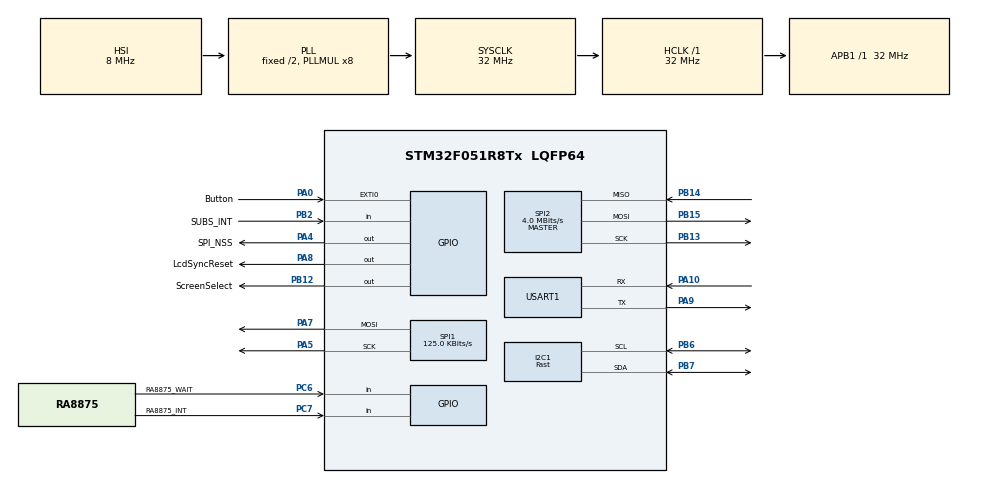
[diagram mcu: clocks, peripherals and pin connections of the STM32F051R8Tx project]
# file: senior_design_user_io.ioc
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I2C1.I2C_Speed_Mode=I2C_Fast
I2C1.Timing=0x0000020B
Mcu.Family=STM32F0
Mcu.Name=STM32F051R8Tx
Mcu.Package=LQFP64
NVIC.EXTI0_1_IRQn=true\:0\:0\:false\:false\:true\:true\:true
PA0.GPIO_Label=Button
PA0.GPIO_PuPd=GPIO_PULLDOWN
PA0.Signal=GPXTI0
PA10.Mode=Asynchronous
PA10.Signal=USART1_RX
PA13.Mode=Serial_Wire
PA13.Signal=SYS_SWDIO
PA14.Mode=Serial_Wire
PA14.Signal=SYS_SWCLK
PA4.GPIO_Label=SPI_NSS
PA4.GPIO_PuPd=GPIO_PULLUP
PA4.GPIO_Speed=GPIO_SPEED_FREQ_HIGH
PA4.PinState=GPIO_PIN_SET
PA4.Signal=GPIO_Output
PA5.Mode=TX_Only_Simplex_Unidirect_Master
PA5.Signal=SPI1_SCK
PA7.Mode=TX_Only_Simplex_Unidirect_Master
PA7.Signal=SPI1_MOSI
PA8.GPIO_Label=LcdSyncReset
PA8.Signal=GPIO_Output
PA9.Mode=Asynchronous
PA9.Signal=USART1_TX
PB12.GPIO_Label=ScreenSelect
PB12.Signal=GPIO_Output
PB13.Mode=Full_Duplex_Master
PB13.Signal=SPI2_SCK
PB14.Mode=Full_Duplex_Master
PB14.Signal=SPI2_MISO
PB15.Mode=Full_Duplex_Master
PB15.Signal=SPI2_MOSI
PB2.GPIO_Label=SUBS_INT
PB2.Signal=GPIO_Input
PB6.Mode=I2C
PB6.Signal=I2C1_SCL
PB7.Mode=I2C
PB7.Signal=I2C1_SDA
PC6.GPIO_Label=RA8875_WAIT
PC6.Signal=GPIO_Input
PC7.GPIO_Label=RA8875_INT
PC7.Signal=GPIO_Input
PF0-OSC_IN.Mode=HSE-External-Oscillator
PF0-OSC_IN.Signal=RCC_OSC_IN
PF1-OSC_OUT.Mode=HSE-External-Oscillator
PF1-OSC_OUT.Signal=RCC_OSC_OUT
ProjectManager.HeapSize=0x200
ProjectManager.StackSize=0x400
ProjectManager.TargetToolchain=STM32CubeIDE
RCC.AHBFreq_Value=32000000
RCC.APB1Freq_Value=32000000
RCC.APB1TimFreq_Value=32000000
RCC.HCLKFreq_Value=32000000
RCC.PLLMUL=RCC_PLL_MUL8
RCC.SYSCLKFreq_VALUE=32000000
RCC.SYSCLKSource=RCC_SYSCLKSOURCE_PLLCLK
SPI1.BaudRatePrescaler=SPI_BAUDRATEPRESCALER_256
SPI1.CalculateBaudRate=125.0 KBits/s
SPI1.DataSize=SPI_DATASIZE_16BIT
SPI1.Direction=SPI_DIRECTION_2LINES
SPI1.Mode=SPI_MODE_MASTER
SPI1.VirtualType=VM_MASTER
SPI2.BaudRatePrescaler=SPI_BAUDRATEPRESCALER_8
SPI2.CLKPhase=SPI_PHASE_1EDGE
SPI2.CalculateBaudRate=4.0 MBits/s
SPI2.DataSize=SPI_DATASIZE_8BIT
SPI2.Direction=SPI_DIRECTION_2LINES
SPI2.Mode=SPI_MODE_MASTER
SPI2.TIMode=SPI_TIMODE_DISABLE
SPI2.VirtualType=VM_MASTER
USART1.VirtualMode-Asynchronous=VM_ASYNC
board=custom

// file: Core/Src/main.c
/* USER CODE BEGIN Header */
/**
  ******************************************************************************
  * @file           : main.c
  * @brief          : Main program body
  ******************************************************************************
  * @attention
  *
  * <h2><center>&copy; Copyright (c) 2021 STMicroelectronics.
  * All rights reserved.</center></h2>
  *
  * This software component is licensed by ST under BSD 3-Clause license,
  * the "License"; You may not use this file except in compliance with the
  * License. You may obtain a copy of the License at:
  *                        opensource.org/licenses/BSD-3-Clause
  *
  ******************************************************************************
  */
/* USER CODE END Header */
#include "main.h"

/* USER CODE BEGIN Includes */
#include "user_io.h"
/* USER CODE END Includes */

I2C_HandleTypeDef hi2c1;

SPI_HandleTypeDef hspi1;
SPI_HandleTypeDef hspi2;

UART_HandleTypeDef huart1;

void SystemClock_Config(void);
static void MX_GPIO_Init(void);
static void MX_SPI1_Init(void);
static void MX_SPI2_Init(void);
static void MX_I2C1_Init(void);
static void MX_USART1_UART_Init(void);

/* USER CODE BEGIN 0 */
void HAL_GPIO_EXTI_Callback(uint16_t Gpio_Pin) {
	if(Gpio_Pin == Button_Pin) {
		process_button();
	}
}
void HAL_SPI_TxCpltCallback(SPI_HandleTypeDef *hspi1) {
	process_spi();
	return;
}
void TransferComplete(DMA_HandleTypeDef *_hdma) {
	return;
}
/* USER CODE END 0 */

int main(void)
{

  /* MCU Configuration--------------------------------------------------------*/

  /* Reset of all peripherals, Initializes the Flash interface and the Systick. */
  HAL_Init();

  /* Configure the system clock */
  SystemClock_Config();

  /* Initialize all configured peripherals */
  MX_GPIO_Init();
  MX_SPI1_Init();
  MX_SPI2_Init();
  MX_I2C1_Init();
  MX_USART1_UART_Init();
  /* USER CODE BEGIN 2 */
  //HAL_DMA_RegisterCallback(&hdma_spi1_tx, HAL_DMA_XFER_CPLT_CB_ID, TransferComplete);
  HAL_GPIO_WritePin(SPI_NSS_GPIO_Port, SPI_NSS_Pin, SET);
  ui_setup(hi2c1, hspi1, hspi2);
  /* USER CODE END 2 */

  /* Infinite loop */
  while (1)
  {

    /* USER CODE BEGIN 3 */
	ui_loop();
  }
  /* USER CODE END 3 */
}

void SystemClock_Config(void)
{
  RCC_OscInitTypeDef RCC_OscInitStruct = {0};
  RCC_ClkInitTypeDef RCC_ClkInitStruct = {0};
  RCC_PeriphCLKInitTypeDef PeriphClkInit = {0};

  /** Initializes the RCC Oscillators according to the specified parameters
  * in the RCC_OscInitTypeDef structure.
  */
  RCC_OscInitStruct.OscillatorType = RCC_OSCILLATORTYPE_HSI;
  RCC_OscInitStruct.HSIState = RCC_HSI_ON;
  RCC_OscInitStruct.HSICalibrationValue = RCC_HSICALIBRATION_DEFAULT;
  RCC_OscInitStruct.PLL.PLLState = RCC_PLL_ON;
  RCC_OscInitStruct.PLL.PLLSource = RCC_PLLSOURCE_HSI;
  RCC_OscInitStruct.PLL.PLLMUL = RCC_PLL_MUL8;
  RCC_OscInitStruct.PLL.PREDIV = RCC_PREDIV_DIV1;
  if (HAL_RCC_OscConfig(&RCC_OscInitStruct) != HAL_OK)
  {
    Error_Handler();
  }
  /** Initializes the CPU, AHB and APB buses clocks
  */
  RCC_ClkInitStruct.ClockType = RCC_CLOCKTYPE_HCLK|RCC_CLOCKTYPE_SYSCLK
                              |RCC_CLOCKTYPE_PCLK1;
  RCC_ClkInitStruct.SYSCLKSource = RCC_SYSCLKSOURCE_PLLCLK;
  RCC_ClkInitStruct.AHBCLKDivider = RCC_SYSCLK_DIV1;
  RCC_ClkInitStruct.APB1CLKDivider = RCC_HCLK_DIV1;

  if (HAL_RCC_ClockConfig(&RCC_ClkInitStruct, FLASH_LATENCY_1) != HAL_OK)
  {
    Error_Handler();
  }
  PeriphClkInit.PeriphClockSelection = RCC_PERIPHCLK_USART1|RCC_PERIPHCLK_I2C1;
  PeriphClkInit.Usart1ClockSelection = RCC_USART1CLKSOURCE_PCLK1;
  PeriphClkInit.I2c1ClockSelection = RCC_I2C1CLKSOURCE_HSI;
  if (HAL_RCCEx_PeriphCLKConfig(&PeriphClkInit) != HAL_OK)
  {
    Error_Handler();
  }
}

static void MX_I2C1_Init(void)
{

  hi2c1.Instance = I2C1;
  hi2c1.Init.Timing = 0x0000020B;
  hi2c1.Init.OwnAddress1 = 0;
  hi2c1.Init.AddressingMode = I2C_ADDRESSINGMODE_7BIT;
  hi2c1.Init.DualAddressMode = I2C_DUALADDRESS_DISABLE;
  hi2c1.Init.OwnAddress2 = 0;
  hi2c1.Init.OwnAddress2Masks = I2C_OA2_NOMASK;
  hi2c1.Init.GeneralCallMode = I2C_GENERALCALL_DISABLE;
  hi2c1.Init.NoStretchMode = I2C_NOSTRETCH_DISABLE;
  if (HAL_I2C_Init(&hi2c1) != HAL_OK)
  {
    Error_Handler();
  }
  /** Configure Analogue filter
  */
  if (HAL_I2CEx_ConfigAnalogFilter(&hi2c1, I2C_ANALOGFILTER_ENABLE) != HAL_OK)
  {
    Error_Handler();
  }
  /** Configure Digital filter
  */
  if (HAL_I2CEx_ConfigDigitalFilter(&hi2c1, 0) != HAL_OK)
  {
    Error_Handler();
  }

}

static void MX_SPI1_Init(void)
{

  /* SPI1 parameter configuration*/
  hspi1.Instance = SPI1;
  hspi1.Init.Mode = SPI_MODE_MASTER;
  hspi1.Init.Direction = SPI_DIRECTION_2LINES;
  hspi1.Init.DataSize = SPI_DATASIZE_16BIT;
  hspi1.Init.CLKPolarity = SPI_POLARITY_LOW;
  hspi1.Init.CLKPhase = SPI_PHASE_1EDGE;
  hspi1.Init.NSS = SPI_NSS_SOFT;
  hspi1.Init.BaudRatePrescaler = SPI_BAUDRATEPRESCALER_256;
  hspi1.Init.FirstBit = SPI_FIRSTBIT_MSB;
  hspi1.Init.TIMode = SPI_TIMODE_DISABLE;
  hspi1.Init.CRCCalculation = SPI_CRCCALCULATION_DISABLE;
  hspi1.Init.CRCPolynomial = 7;
  hspi1.Init.CRCLength = SPI_CRC_LENGTH_DATASIZE;
  hspi1.Init.NSSPMode = SPI_NSS_PULSE_ENABLE;
  if (HAL_SPI_Init(&hspi1) != HAL_OK)
  {
    Error_Handler();
  }

}

static void MX_SPI2_Init(void)
{

  /* SPI2 parameter configuration*/
  hspi2.Instance = SPI2;
  hspi2.Init.Mode = SPI_MODE_MASTER;
  hspi2.Init.Direction = SPI_DIRECTION_2LINES;
  hspi2.Init.DataSize = SPI_DATASIZE_8BIT;
  hspi2.Init.CLKPolarity = SPI_POLARITY_LOW;
  hspi2.Init.CLKPhase = SPI_PHASE_1EDGE;
  hspi2.Init.NSS = SPI_NSS_SOFT;
  hspi2.Init.BaudRatePrescaler = SPI_BAUDRATEPRESCALER_8;
  hspi2.Init.FirstBit = SPI_FIRSTBIT_MSB;
  hspi2.Init.TIMode = SPI_TIMODE_DISABLE;
  hspi2.Init.CRCCalculation = SPI_CRCCALCULATION_DISABLE;
  hspi2.Init.CRCPolynomial = 7;
  hspi2.Init.CRCLength = SPI_CRC_LENGTH_DATASIZE;
  hspi2.Init.NSSPMode = SPI_NSS_PULSE_ENABLE;
  if (HAL_SPI_Init(&hspi2) != HAL_OK)
  {
    Error_Handler();
  }

}

static void MX_USART1_UART_Init(void)
{

  huart1.Instance = USART1;
  huart1.Init.BaudRate = 38400;
  huart1.Init.WordLength = UART_WORDLENGTH_8B;
  huart1.Init.StopBits = UART_STOPBITS_1;
  huart1.Init.Parity = UART_PARITY_NONE;
  huart1.Init.Mode = UART_MODE_TX_RX;
  huart1.Init.HwFlowCtl = UART_HWCONTROL_NONE;
  huart1.Init.OverSampling = UART_OVERSAMPLING_16;
  huart1.Init.OneBitSampling = UART_ONE_BIT_SAMPLE_DISABLE;
  huart1.AdvancedInit.AdvFeatureInit = UART_ADVFEATURE_NO_INIT;
  if (HAL_UART_Init(&huart1) != HAL_OK)
  {
    Error_Handler();
  }

}

static void MX_GPIO_Init(void)
{
  GPIO_InitTypeDef GPIO_InitStruct = {0};

  /* GPIO Ports Clock Enable */
  __HAL_RCC_GPIOF_CLK_ENABLE();
  __HAL_RCC_GPIOA_CLK_ENABLE();
  __HAL_RCC_GPIOB_CLK_ENABLE();
  __HAL_RCC_GPIOC_CLK_ENABLE();

  /*Configure GPIO pin Output Level */
  HAL_GPIO_WritePin(SPI_NSS_GPIO_Port, SPI_NSS_Pin, GPIO_PIN_SET);

  /*Configure GPIO pin Output Level */
  HAL_GPIO_WritePin(ScreenSelect_GPIO_Port, ScreenSelect_Pin, GPIO_PIN_RESET);

  /*Configure GPIO pin Output Level */
  HAL_GPIO_WritePin(LcdSyncReset_GPIO_Port, LcdSyncReset_Pin, GPIO_PIN_RESET);

  /*Configure GPIO pin : Button_Pin */
  GPIO_InitStruct.Pin = Button_Pin;
  GPIO_InitStruct.Mode = GPIO_MODE_IT_RISING;
  GPIO_InitStruct.Pull = GPIO_PULLDOWN;
  HAL_GPIO_Init(Button_GPIO_Port, &GPIO_InitStruct);

  /*Configure GPIO pin : SPI_NSS_Pin */
  GPIO_InitStruct.Pin = SPI_NSS_Pin;
  GPIO_InitStruct.Mode = GPIO_MODE_OUTPUT_PP;
  GPIO_InitStruct.Pull = GPIO_PULLUP;
  GPIO_InitStruct.Speed = GPIO_SPEED_FREQ_HIGH;
  HAL_GPIO_Init(SPI_NSS_GPIO_Port, &GPIO_InitStruct);

  /*Configure GPIO pin : SUBS_INT_Pin */
  GPIO_InitStruct.Pin = SUBS_INT_Pin;
  GPIO_InitStruct.Mode = GPIO_MODE_INPUT;
  GPIO_InitStruct.Pull = GPIO_NOPULL;
  HAL_GPIO_Init(SUBS_INT_GPIO_Port, &GPIO_InitStruct);

  /*Configure GPIO pin : ScreenSelect_Pin */
  GPIO_InitStruct.Pin = ScreenSelect_Pin;
  GPIO_InitStruct.Mode = GPIO_MODE_OUTPUT_PP;
  GPIO_InitStruct.Pull = GPIO_NOPULL;
  GPIO_InitStruct.Speed = GPIO_SPEED_FREQ_LOW;
  HAL_GPIO_Init(ScreenSelect_GPIO_Port, &GPIO_InitStruct);

  /*Configure GPIO pins : RA8875_WAIT_Pin RA8875_INT_Pin */
  GPIO_InitStruct.Pin = RA8875_WAIT_Pin|RA8875_INT_Pin;
  GPIO_InitStruct.Mode = GPIO_MODE_INPUT;
  GPIO_InitStruct.Pull = GPIO_NOPULL;
  HAL_GPIO_Init(GPIOC, &GPIO_InitStruct);

  /*Configure GPIO pin : LcdSyncReset_Pin */
  GPIO_InitStruct.Pin = LcdSyncReset_Pin;
  GPIO_InitStruct.Mode = GPIO_MODE_OUTPUT_PP;
  GPIO_InitStruct.Pull = GPIO_NOPULL;
  GPIO_InitStruct.Speed = GPIO_SPEED_FREQ_LOW;
  HAL_GPIO_Init(LcdSyncReset_GPIO_Port, &GPIO_InitStruct);

  /* EXTI interrupt init*/
  HAL_NVIC_SetPriority(EXTI0_1_IRQn, 0, 0);
  HAL_NVIC_EnableIRQ(EXTI0_1_IRQn);

}

void Error_Handler(void)
{
  __disable_irq();
  while (1)
  {
  }
}

/************************ (C) COPYRIGHT STMicroelectronics *****END OF FILE****/
